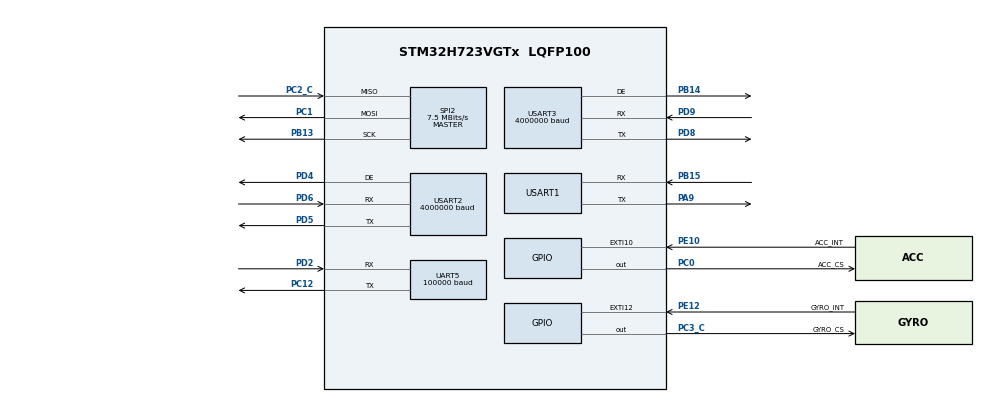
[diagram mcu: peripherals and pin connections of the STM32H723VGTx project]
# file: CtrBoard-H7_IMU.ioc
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Dma.Request0=SPI2_RX
Dma.Request1=SPI2_TX
Dma.Request2=USART2_RX
Dma.Request3=USART2_TX
Dma.Request4=USART3_RX
Dma.Request5=USART3_TX
Dma.Request6=USART1_RX
Dma.Request7=USART1_TX
Dma.SPI2_RX.0.Direction=DMA_PERIPH_TO_MEMORY
Dma.SPI2_RX.0.EventEnable=DISABLE
Dma.SPI2_RX.0.FIFOMode=DMA_FIFOMODE_DISABLE
Dma.SPI2_RX.0.Instance=DMA1_Stream0
Dma.SPI2_RX.0.MemDataAlignment=DMA_MDATAALIGN_BYTE
Dma.SPI2_RX.0.MemInc=DMA_MINC_ENABLE
Dma.SPI2_RX.0.Mode=DMA_NORMAL
Dma.SPI2_RX.0.PeriphDataAlignment=DMA_PDATAALIGN_BYTE
Dma.SPI2_RX.0.PeriphInc=DMA_PINC_DISABLE
Dma.SPI2_RX.0.Polarity=HAL_DMAMUX_REQ_GEN_RISING
Dma.SPI2_RX.0.Priority=DMA_PRIORITY_VERY_HIGH
Dma.SPI2_RX.0.RequestNumber=1
Dma.SPI2_RX.0.SignalID=NONE
Dma.SPI2_RX.0.SyncEnable=DISABLE
Dma.SPI2_RX.0.SyncPolarity=HAL_DMAMUX_SYNC_NO_EVENT
Dma.SPI2_RX.0.SyncRequestNumber=1
Dma.SPI2_RX.0.SyncSignalID=NONE
Dma.SPI2_TX.1.Direction=DMA_MEMORY_TO_PERIPH
Dma.SPI2_TX.1.EventEnable=DISABLE
Dma.SPI2_TX.1.FIFOMode=DMA_FIFOMODE_DISABLE
Dma.SPI2_TX.1.Instance=DMA1_Stream1
Dma.SPI2_TX.1.MemDataAlignment=DMA_MDATAALIGN_BYTE
Dma.SPI2_TX.1.MemInc=DMA_MINC_ENABLE
Dma.SPI2_TX.1.Mode=DMA_NORMAL
Dma.SPI2_TX.1.PeriphDataAlignment=DMA_PDATAALIGN_BYTE
Dma.SPI2_TX.1.PeriphInc=DMA_PINC_DISABLE
Dma.SPI2_TX.1.Polarity=HAL_DMAMUX_REQ_GEN_RISING
Dma.SPI2_TX.1.Priority=DMA_PRIORITY_HIGH
Dma.SPI2_TX.1.RequestNumber=1
Dma.SPI2_TX.1.SignalID=NONE
Dma.SPI2_TX.1.SyncEnable=DISABLE
Dma.SPI2_TX.1.SyncPolarity=HAL_DMAMUX_SYNC_NO_EVENT
Dma.SPI2_TX.1.SyncRequestNumber=1
Dma.SPI2_TX.1.SyncSignalID=NONE
Dma.USART1_RX.6.Direction=DMA_PERIPH_TO_MEMORY
Dma.USART1_RX.6.EventEnable=DISABLE
Dma.USART1_RX.6.FIFOMode=DMA_FIFOMODE_DISABLE
Dma.USART1_RX.6.Instance=DMA1_Stream6
Dma.USART1_RX.6.MemDataAlignment=DMA_MDATAALIGN_BYTE
Dma.USART1_RX.6.MemInc=DMA_MINC_ENABLE
Dma.USART1_RX.6.Mode=DMA_NORMAL
Dma.USART1_RX.6.PeriphDataAlignment=DMA_PDATAALIGN_BYTE
Dma.USART1_RX.6.PeriphInc=DMA_PINC_DISABLE
Dma.USART1_RX.6.Polarity=HAL_DMAMUX_REQ_GEN_RISING
Dma.USART1_RX.6.Priority=DMA_PRIORITY_LOW
Dma.USART1_RX.6.RequestNumber=1
Dma.USART1_RX.6.SignalID=NONE
Dma.USART1_RX.6.SyncEnable=DISABLE
Dma.USART1_RX.6.SyncPolarity=HAL_DMAMUX_SYNC_NO_EVENT
Dma.USART1_RX.6.SyncRequestNumber=1
Dma.USART1_RX.6.SyncSignalID=NONE
Dma.USART1_TX.7.Direction=DMA_MEMORY_TO_PERIPH
Dma.USART1_TX.7.EventEnable=DISABLE
Dma.USART1_TX.7.FIFOMode=DMA_FIFOMODE_DISABLE
Dma.USART1_TX.7.Instance=DMA1_Stream7
Dma.USART1_TX.7.MemDataAlignment=DMA_MDATAALIGN_BYTE
Dma.USART1_TX.7.MemInc=DMA_MINC_ENABLE
Dma.USART1_TX.7.Mode=DMA_NORMAL
Dma.USART1_TX.7.PeriphDataAlignment=DMA_PDATAALIGN_BYTE
Dma.USART1_TX.7.PeriphInc=DMA_PINC_DISABLE
Dma.USART1_TX.7.Polarity=HAL_DMAMUX_REQ_GEN_RISING
Dma.USART1_TX.7.Priority=DMA_PRIORITY_LOW
Dma.USART1_TX.7.RequestNumber=1
Dma.USART1_TX.7.SignalID=NONE
Dma.USART1_TX.7.SyncEnable=DISABLE
Dma.USART1_TX.7.SyncPolarity=HAL_DMAMUX_SYNC_NO_EVENT
Dma.USART1_TX.7.SyncRequestNumber=1
Dma.USART1_TX.7.SyncSignalID=NONE
Dma.USART2_RX.2.Direction=DMA_PERIPH_TO_MEMORY
Dma.USART2_RX.2.EventEnable=DISABLE
Dma.USART2_RX.2.FIFOMode=DMA_FIFOMODE_DISABLE
Dma.USART2_RX.2.Instance=DMA1_Stream2
Dma.USART2_RX.2.MemDataAlignment=DMA_MDATAALIGN_BYTE
Dma.USART2_RX.2.MemInc=DMA_MINC_ENABLE
Dma.USART2_RX.2.Mode=DMA_CIRCULAR
Dma.USART2_RX.2.PeriphDataAlignment=DMA_PDATAALIGN_BYTE
Dma.USART2_RX.2.PeriphInc=DMA_PINC_DISABLE
Dma.USART2_RX.2.Polarity=HAL_DMAMUX_REQ_GEN_RISING
Dma.USART2_RX.2.Priority=DMA_PRIORITY_HIGH
Dma.USART2_RX.2.RequestNumber=1
Dma.USART2_RX.2.SignalID=NONE
Dma.USART2_RX.2.SyncEnable=DISABLE
Dma.USART2_RX.2.SyncPolarity=HAL_DMAMUX_SYNC_NO_EVENT
Dma.USART2_RX.2.SyncRequestNumber=1
Dma.USART2_RX.2.SyncSignalID=NONE
Dma.USART2_TX.3.Direction=DMA_MEMORY_TO_PERIPH
Dma.USART2_TX.3.EventEnable=DISABLE
Dma.USART2_TX.3.FIFOMode=DMA_FIFOMODE_DISABLE
Dma.USART2_TX.3.Instance=DMA1_Stream3
Dma.USART2_TX.3.MemDataAlignment=DMA_MDATAALIGN_BYTE
Dma.USART2_TX.3.MemInc=DMA_MINC_ENABLE
Dma.USART2_TX.3.Mode=DMA_NORMAL
Dma.USART2_TX.3.PeriphDataAlignment=DMA_PDATAALIGN_BYTE
Dma.USART2_TX.3.PeriphInc=DMA_PINC_DISABLE
Dma.USART2_TX.3.Polarity=HAL_DMAMUX_REQ_GEN_RISING
Dma.USART2_TX.3.Priority=DMA_PRIORITY_HIGH
Dma.USART2_TX.3.RequestNumber=1
Dma.USART2_TX.3.SignalID=NONE
Dma.USART2_TX.3.SyncEnable=DISABLE
Dma.USART2_TX.3.SyncPolarity=HAL_DMAMUX_SYNC_NO_EVENT
Dma.USART2_TX.3.SyncRequestNumber=1
Dma.USART2_TX.3.SyncSignalID=NONE
Dma.USART3_RX.4.Direction=DMA_PERIPH_TO_MEMORY
Dma.USART3_RX.4.EventEnable=DISABLE
Dma.USART3_RX.4.FIFOMode=DMA_FIFOMODE_DISABLE
Dma.USART3_RX.4.Instance=DMA1_Stream4
Dma.USART3_RX.4.MemDataAlignment=DMA_MDATAALIGN_BYTE
Dma.USART3_RX.4.MemInc=DMA_MINC_ENABLE
Dma.USART3_RX.4.Mode=DMA_CIRCULAR
Dma.USART3_RX.4.PeriphDataAlignment=DMA_PDATAALIGN_BYTE
Dma.USART3_RX.4.PeriphInc=DMA_PINC_DISABLE
Dma.USART3_RX.4.Polarity=HAL_DMAMUX_REQ_GEN_RISING
Dma.USART3_RX.4.Priority=DMA_PRIORITY_HIGH
Dma.USART3_RX.4.RequestNumber=1
Dma.USART3_RX.4.SignalID=NONE
Dma.USART3_RX.4.SyncEnable=DISABLE
Dma.USART3_RX.4.SyncPolarity=HAL_DMAMUX_SYNC_NO_EVENT
Dma.USART3_RX.4.SyncRequestNumber=1
Dma.USART3_RX.4.SyncSignalID=NONE
Dma.USART3_TX.5.Direction=DMA_MEMORY_TO_PERIPH
Dma.USART3_TX.5.EventEnable=DISABLE
Dma.USART3_TX.5.FIFOMode=DMA_FIFOMODE_DISABLE
Dma.USART3_TX.5.Instance=DMA1_Stream5
Dma.USART3_TX.5.MemDataAlignment=DMA_MDATAALIGN_BYTE
Dma.USART3_TX.5.MemInc=DMA_MINC_ENABLE
Dma.USART3_TX.5.Mode=DMA_NORMAL
Dma.USART3_TX.5.PeriphDataAlignment=DMA_PDATAALIGN_BYTE
Dma.USART3_TX.5.PeriphInc=DMA_PINC_DISABLE
Dma.USART3_TX.5.Polarity=HAL_DMAMUX_REQ_GEN_RISING
Dma.USART3_TX.5.Priority=DMA_PRIORITY_HIGH
Dma.USART3_TX.5.RequestNumber=1
Dma.USART3_TX.5.SignalID=NONE
Dma.USART3_TX.5.SyncEnable=DISABLE
Dma.USART3_TX.5.SyncPolarity=HAL_DMAMUX_SYNC_NO_EVENT
Dma.USART3_TX.5.SyncRequestNumber=1
Dma.USART3_TX.5.SyncSignalID=NONE
Mcu.Family=STM32H7
Mcu.Name=STM32H723VGTx
Mcu.Package=LQFP100
NVIC.DMA1_Stream0_IRQn=true\:1\:0\:true\:false\:true\:false\:true\:true
NVIC.DMA1_Stream1_IRQn=true\:2\:0\:true\:false\:true\:false\:true\:true
NVIC.DMA1_Stream2_IRQn=true\:0\:0\:false\:false\:true\:false\:true\:true
NVIC.DMA1_Stream3_IRQn=true\:0\:0\:false\:false\:true\:false\:true\:true
NVIC.DMA1_Stream4_IRQn=true\:0\:0\:false\:false\:true\:false\:true\:true
NVIC.DMA1_Stream5_IRQn=true\:0\:0\:false\:false\:true\:false\:true\:true
NVIC.DMA1_Stream6_IRQn=true\:0\:0\:false\:false\:true\:false\:true\:true
NVIC.DMA1_Stream7_IRQn=true\:0\:0\:false\:false\:true\:false\:true\:true
NVIC.PriorityGroup=NVIC_PRIORITYGROUP_4
NVIC.SPI2_IRQn=true\:5\:0\:true\:false\:true\:false\:true\:true
NVIC.TIM3_IRQn=true\:0\:0\:false\:false\:true\:true\:true\:true
NVIC.TIM8_UP_TIM13_IRQn=true\:0\:0\:false\:false\:true\:true\:true\:true
NVIC.UART5_IRQn=true\:0\:0\:false\:false\:true\:true\:true\:true
NVIC.USART1_IRQn=true\:0\:0\:false\:false\:true\:true\:true\:true
NVIC.USART2_IRQn=true\:0\:0\:false\:false\:true\:true\:true\:true
NVIC.USART3_IRQn=true\:0\:0\:false\:false\:true\:true\:true\:true
PA13(JTMS/SWDIO).Mode=Serial_Wire
PA13(JTMS/SWDIO).Signal=DEBUG_JTMS-SWDIO
PA14(JTCK/SWCLK).Mode=Serial_Wire
PA14(JTCK/SWCLK).Signal=DEBUG_JTCK-SWCLK
PA9.Mode=Asynchronous
PA9.Signal=USART1_TX
PB13.GPIO_Speed=GPIO_SPEED_FREQ_VERY_HIGH
PB13.Mode=Full_Duplex_Master
PB13.Signal=SPI2_SCK
PB14.Mode=Hardware Flow Control (RS485)
PB14.Signal=USART3_DE
PB15.Mode=Asynchronous
PB15.Signal=USART1_RX
PC0.GPIO_Label=ACC_CS
PC0.GPIO_Speed=GPIO_SPEED_FREQ_VERY_HIGH
PC0.PinState=GPIO_PIN_SET
PC0.Signal=GPIO_Output
PC1.GPIO_Speed=GPIO_SPEED_FREQ_VERY_HIGH
PC1.Mode=Full_Duplex_Master
PC1.Signal=SPI2_MOSI
PC12.Mode=Asynchronous
PC12.Signal=UART5_TX
PC2_C.GPIO_Speed=GPIO_SPEED_FREQ_VERY_HIGH
PC2_C.Mode=Full_Duplex_Master
PC2_C.Signal=SPI2_MISO
PC3_C.GPIO_Label=GYRO_CS
PC3_C.GPIO_Speed=GPIO_SPEED_FREQ_VERY_HIGH
PC3_C.PinState=GPIO_PIN_SET
PC3_C.Signal=GPIO_Output
PD2.Mode=Asynchronous
PD2.Signal=UART5_RX
PD4.Mode=Hardware Flow Control (RS485)
PD4.Signal=USART2_DE
PD5.Mode=Asynchronous
PD5.Signal=USART2_TX
PD6.Mode=Asynchronous
PD6.Signal=USART2_RX
PD8.Mode=Asynchronous
PD8.Signal=USART3_TX
PD9.Mode=Asynchronous
PD9.Signal=USART3_RX
PE10.GPIO_Label=ACC_INT
PE10.Signal=GPXTI10
PE12.GPIO_Label=GYRO_INT
PE12.Signal=GPXTI12
PH0-OSC_IN.Mode=HSE-External-Oscillator
PH0-OSC_IN.Signal=RCC_OSC_IN
PH1-OSC_OUT.Mode=HSE-External-Oscillator
PH1-OSC_OUT.Signal=RCC_OSC_OUT
ProjectManager.HeapSize=0x200
ProjectManager.StackSize=0x800
ProjectManager.TargetToolchain=Makefile
RCC.ADCFreq_Value=48375000
RCC.APB1Freq_Value=120000000
RCC.APB2Freq_Value=120000000
RCC.APB3Freq_Value=120000000
RCC.APB4Freq_Value=120000000
RCC.CortexFreq_Value=480000000
RCC.D1PPRE=RCC_APB3_DIV2
RCC.D2PPRE1=RCC_APB1_DIV2
RCC.D2PPRE2=RCC_APB2_DIV2
RCC.D3PPRE=RCC_APB4_DIV2
RCC.DIVM1=2
RCC.DIVN1=40
RCC.DIVP1=1
RCC.HCLKFreq_Value=240000000
RCC.HPRE=RCC_HCLK_DIV2
RCC.HSE_VALUE=24000000
RCC.PLL2FRACN=0
RCC.PLL3FRACN=0
RCC.PLLFRACN=0
RCC.PLLSourceVirtual=RCC_PLLSOURCE_HSE
RCC.SYSCLKFreq_VALUE=480000000
RCC.SYSCLKSource=RCC_SYSCLKSOURCE_PLLCLK
RCC.USBFreq_Value=240000000
SPI2.BaudRatePrescaler=SPI_BAUDRATEPRESCALER_32
SPI2.CLKPhase=SPI_PHASE_2EDGE
SPI2.CLKPolarity=SPI_POLARITY_HIGH
SPI2.CalculateBaudRate=7.5 MBits/s
SPI2.DataSize=SPI_DATASIZE_8BIT
SPI2.Direction=SPI_DIRECTION_2LINES
SPI2.Mode=SPI_MODE_MASTER
SPI2.VirtualType=VM_MASTER
TIM3.Period=3000-1
TIM3.Prescaler=240-1
TIM8.ClockDivision=TIM_CLOCKDIVISION_DIV1
TIM8.Period=999
TIM8.Prescaler=239
UART5.BaudRate=100000
UART5.DataInvertParam=UART_ADVFEATURE_DATAINV_DISABLE
UART5.Parity=PARITY_EVEN
UART5.StopBits=UART_STOPBITS_2
UART5.WordLength=WORDLENGTH_9B
USART1.VirtualMode-Asynchronous=VM_ASYNC
USART2.BaudRate=4000000
USART2.VirtualMode-Asynchronous=VM_ASYNC
USART2.VirtualMode-Hardware\ Flow\ Control\ (RS485)=VM_ASYNC
USART3.BaudRate=4000000
USART3.VirtualMode-Asynchronous=VM_ASYNC
USART3.VirtualMode-Hardware\ Flow\ Control\ (RS485)=VM_ASYNC
VP_MEMORYMAP_VS_MEMORYMAP.Mode=CurAppReg
VP_TIM3_VS_ClockSourceINT.Mode=Internal
VP_TIM8_VS_ClockSourceINT.Mode=Internal
board=custom

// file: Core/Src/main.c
/* USER CODE BEGIN Header */
/**
  ******************************************************************************
  * @file           : main.c
  * @brief          : Main program body
  ******************************************************************************
  * @attention
  *
  * Copyright (c) 2024 STMicroelectronics.
  * All rights reserved.
  *
  * This software is licensed under terms that can be found in the LICENSE file
  * in the root directory of this software component.
  * If no LICENSE file comes with this software, it is provided AS-IS.
  *
  ******************************************************************************
  */
/* USER CODE END Header */
#include "main.h"
#include "dma.h"
#include "spi.h"
#include "tim.h"
#include "usart.h"
#include "gpio.h"

/* USER CODE BEGIN Includes */
#include "BMI088driver.h"
#include "control_task.h"
#include "motor_task.h"
#include "dog.h"
/* USER CODE END Includes */

void SystemClock_Config(void);

/* USER CODE BEGIN 0 */
// float gyro[3], accel[3], temp;
/* USER CODE END 0 */

int main(void)
{

  /* MCU Configuration--------------------------------------------------------*/

  /* Reset of all peripherals, Initializes the Flash interface and the Systick. */
  HAL_Init();

  /* Configure the system clock */
  SystemClock_Config();

  /* Initialize all configured peripherals */
  MX_GPIO_Init();
  MX_DMA_Init();
  MX_SPI2_Init();
  MX_UART5_Init();
  MX_USART2_UART_Init();
  MX_USART3_UART_Init();
  MX_TIM8_Init();
  MX_USART1_UART_Init();
  MX_TIM3_Init();
  /* USER CODE BEGIN 2 */
  if (control_task_init() == 0U)
  {
    Error_Handler();
  }
  leg_init();                                       //给腿设参数
  // HAL_Delay(2000);
  // 软件测试使用预设参考值；实物在已知姿态下再采集。
  // Leg_Initpos_Reset();                             //记录当前的角度，和init的值形成对照

    // while(BMI088_init())
    // {
    //     ;
    // }

  // 电机力矩测试仅由TIM8发送，避免足端控制覆盖测试目标。
  // start_enter();
  // __HAL_TIM_SET_COUNTER(&htim3, 0);                // 清零计数器
  // __HAL_TIM_CLEAR_FLAG(&htim3, TIM_FLAG_UPDATE);  // 清除残留更新标志
  // HAL_TIM_Base_Start_IT(&htim3);
  // motor_test();

  /* USER CODE END 2 */

  /* Infinite loop */
  while (1)
  {
    // Get_Now_Pos_Spd(0);
    // HAL_Delay(10);
    /* USER CODE BEGIN 3 */
    control_task ();
  }
  /* USER CODE END 3 */
}

void SystemClock_Config(void)
{
  RCC_OscInitTypeDef RCC_OscInitStruct = {0};
  RCC_ClkInitTypeDef RCC_ClkInitStruct = {0};

  /** Supply configuration update enable
  */
  HAL_PWREx_ConfigSupply(PWR_LDO_SUPPLY);

  /** Configure the main internal regulator output voltage
  */
  __HAL_PWR_VOLTAGESCALING_CONFIG(PWR_REGULATOR_VOLTAGE_SCALE0);

  while(!__HAL_PWR_GET_FLAG(PWR_FLAG_VOSRDY)) {}

  /** Initializes the RCC Oscillators according to the specified parameters
  * in the RCC_OscInitTypeDef structure.
  */
  RCC_OscInitStruct.OscillatorType = RCC_OSCILLATORTYPE_HSE;
  RCC_OscInitStruct.HSEState = RCC_HSE_ON;
  RCC_OscInitStruct.PLL.PLLState = RCC_PLL_ON;
  RCC_OscInitStruct.PLL.PLLSource = RCC_PLLSOURCE_HSE;
  RCC_OscInitStruct.PLL.PLLM = 2;
  RCC_OscInitStruct.PLL.PLLN = 40;
  RCC_OscInitStruct.PLL.PLLP = 1;
  RCC_OscInitStruct.PLL.PLLQ = 2;
  RCC_OscInitStruct.PLL.PLLR = 2;
  RCC_OscInitStruct.PLL.PLLRGE = RCC_PLL1VCIRANGE_3;
  RCC_OscInitStruct.PLL.PLLVCOSEL = RCC_PLL1VCOWIDE;
  RCC_OscInitStruct.PLL.PLLFRACN = 0;
  if (HAL_RCC_OscConfig(&RCC_OscInitStruct) != HAL_OK)
  {
    Error_Handler();
  }

  /** Initializes the CPU, AHB and APB buses clocks
  */
  RCC_ClkInitStruct.ClockType = RCC_CLOCKTYPE_HCLK|RCC_CLOCKTYPE_SYSCLK
                              |RCC_CLOCKTYPE_PCLK1|RCC_CLOCKTYPE_PCLK2
                              |RCC_CLOCKTYPE_D3PCLK1|RCC_CLOCKTYPE_D1PCLK1;
  RCC_ClkInitStruct.SYSCLKSource = RCC_SYSCLKSOURCE_PLLCLK;
  RCC_ClkInitStruct.SYSCLKDivider = RCC_SYSCLK_DIV1;
  RCC_ClkInitStruct.AHBCLKDivider = RCC_HCLK_DIV2;
  RCC_ClkInitStruct.APB3CLKDivider = RCC_APB3_DIV2;
  RCC_ClkInitStruct.APB1CLKDivider = RCC_APB1_DIV2;
  RCC_ClkInitStruct.APB2CLKDivider = RCC_APB2_DIV2;
  RCC_ClkInitStruct.APB4CLKDivider = RCC_APB4_DIV2;

  if (HAL_RCC_ClockConfig(&RCC_ClkInitStruct, FLASH_LATENCY_3) != HAL_OK)
  {
    Error_Handler();
  }
}

void Error_Handler(void)
{
  __disable_irq();
  while (1)
  {
  }
}
